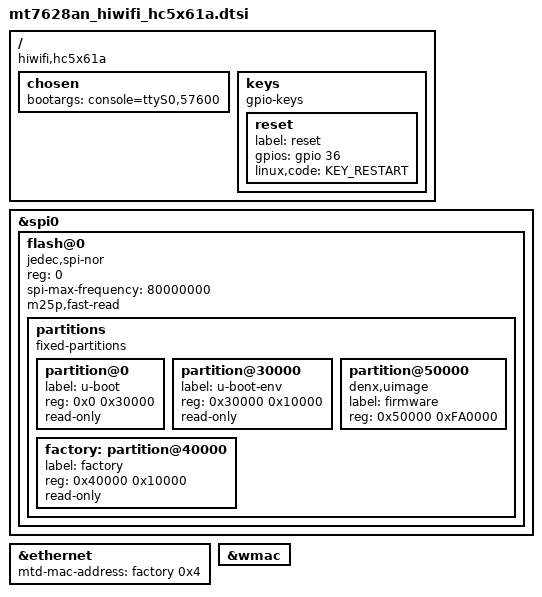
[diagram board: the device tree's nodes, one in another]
// SPDX-License-Identifier: GPL-2.0-or-later OR MIT

#include "mt7628an.dtsi"

#include <dt-bindings/gpio/gpio.h>
#include <dt-bindings/input/input.h>

/ {
	compatible = "hiwifi,hc5x61a", "mediatek,mt7628an-soc";

	chosen {
		bootargs = "console=ttyS0,57600";
	};

	keys {
		compatible = "gpio-keys";

		reset {
			label = "reset";
			gpios = <&gpio 36 GPIO_ACTIVE_HIGH>;
			linux,code = <KEY_RESTART>;
		};
	};
};

&spi0 {
	status = "okay";

	flash@0 {
		compatible = "jedec,spi-nor";
		reg = <0>;
		spi-max-frequency = <80000000>;
		m25p,fast-read;

		partitions {
			compatible = "fixed-partitions";
			#address-cells = <1>;
			#size-cells = <1>;

			partition@0 {
				label = "u-boot";
				reg = <0x0 0x30000>;
				read-only;
			};

			partition@30000 {
				label = "u-boot-env";
				reg = <0x30000 0x10000>;
				read-only;
			};

			factory: partition@40000 {
				label = "factory";
				reg = <0x40000 0x10000>;
				read-only;
			};

			partition@50000 {
				compatible = "denx,uimage";
				label = "firmware";
				reg = <0x50000 0xFA0000>;
			};
		};
	};
};

&ethernet {
	mtd-mac-address = <&factory 0x4>;
};

&wmac {
	status = "okay";
};
